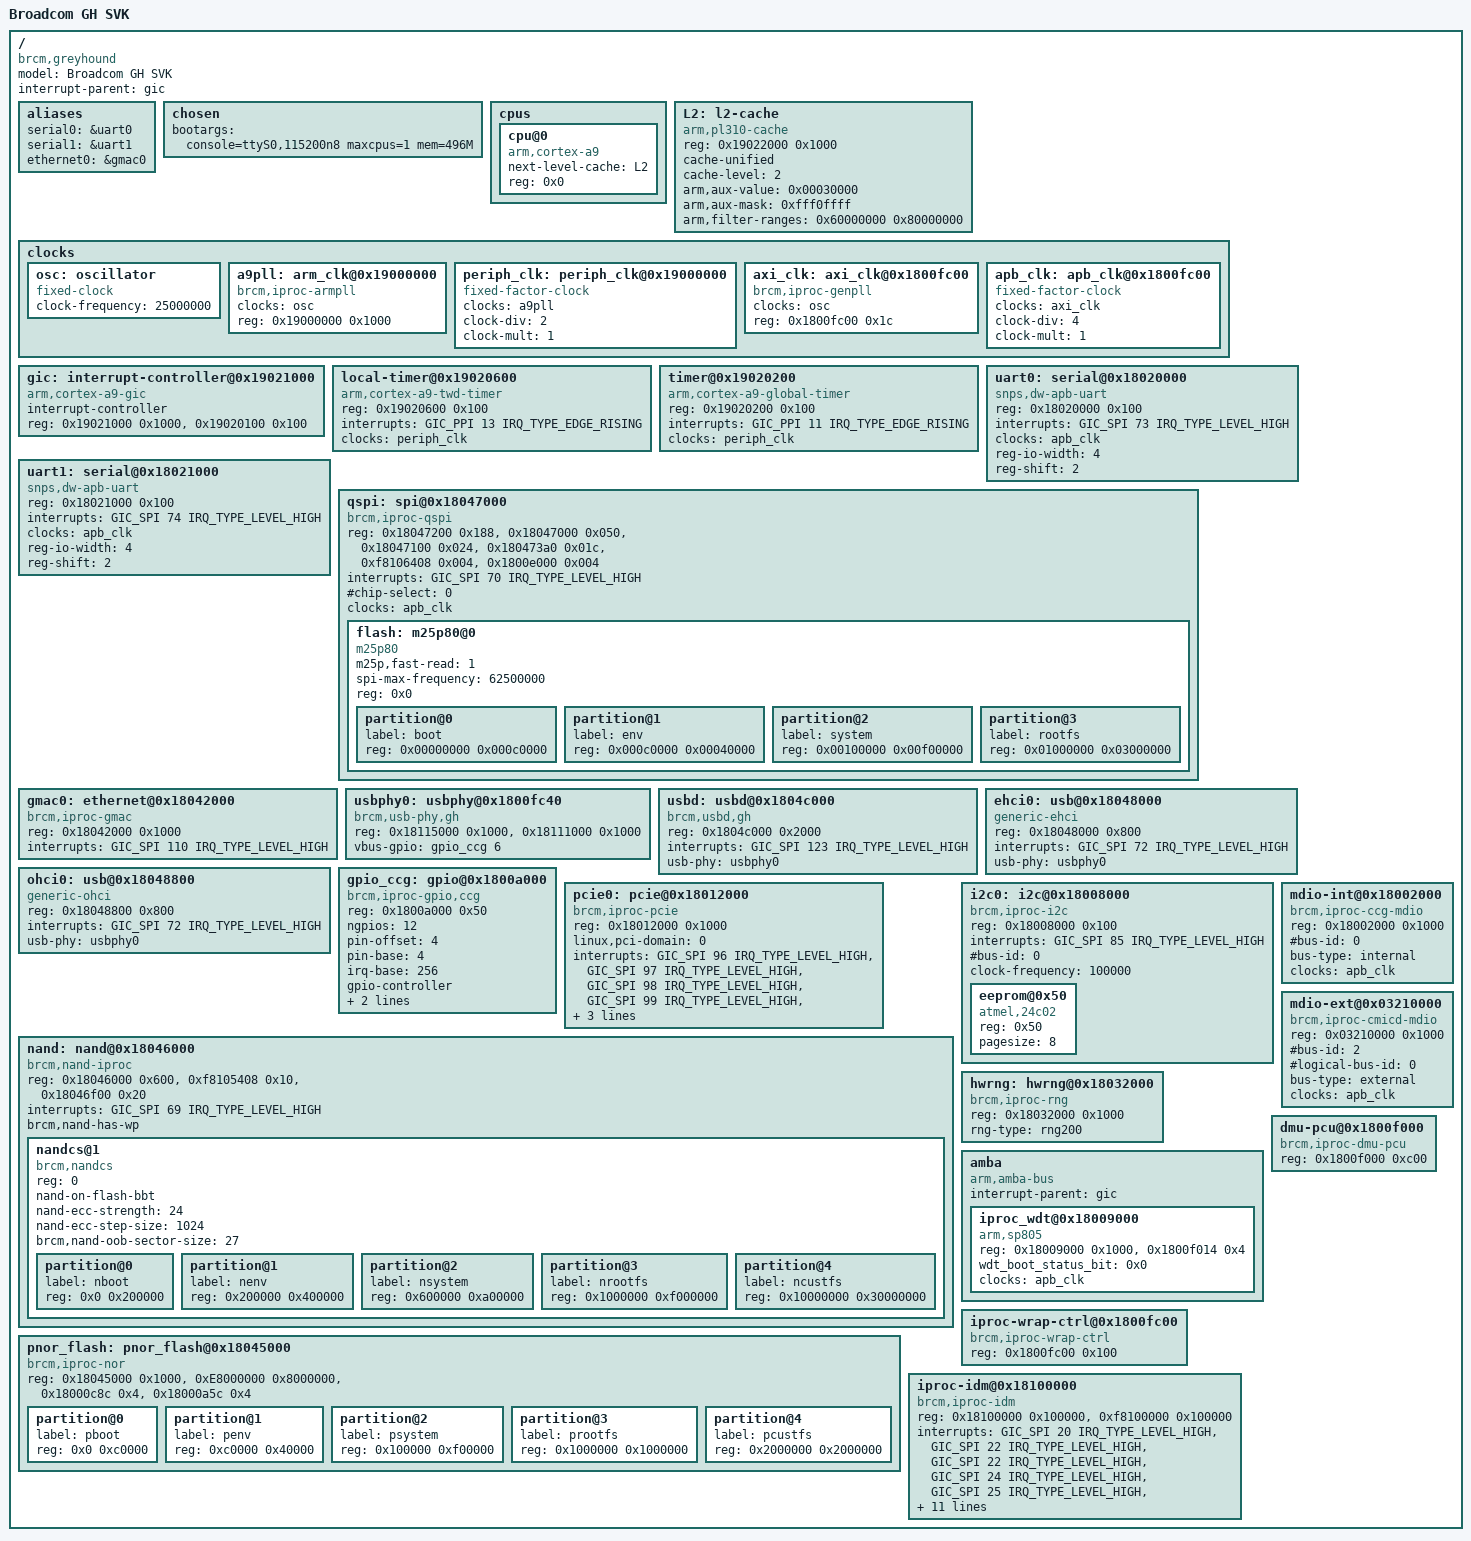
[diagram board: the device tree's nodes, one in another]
/*
 GH DTS
*/

/dts-v1/;

#include <dt-bindings/interrupt-controller/arm-gic.h>
#include <dt-bindings/gpio/gpio.h>
#include "skeleton.dtsi"


/ {
	model = "Broadcom GH SVK";
	compatible = "brcm,greyhound", "brcm,iproc-p7";
	interrupt-parent = <&gic>;

	aliases {
		serial0 = &uart0;
		serial1 = &uart1;
		ethernet0 = &gmac0;
	};
	
	chosen {
		bootargs = "console=ttyS0,115200n8 maxcpus=1 mem=496M";
	};

	cpus {
		#address-cells = <1>;
		#size-cells = <0>;

		cpu@0 {
			device_type = "cpu";
			compatible = "arm,cortex-a9";
			next-level-cache = <&L2>;
			reg = <0x0>;
		};
	};
  	
  	L2: l2-cache {
		compatible = "arm,pl310-cache";
		reg = <0x19022000 0x1000>;
		cache-unified;
		cache-level = <2>;
		/* aux register value */
		arm,aux-value = <0x00030000>;
		arm,aux-mask = <0xfff0ffff>;
		arm,filter-ranges = <0x60000000 0x80000000>;
		/*arm,data-latency = <2 2 2>;*/
		/*arm,tag-latency = <1 1 1>;*/
	};
  	
  	clocks {
		#address-cells = <1>;
		#size-cells = <1>;
		ranges;

		osc: oscillator {
			#clock-cells = <0>;
			compatible = "fixed-clock";
			clock-frequency = <25000000>;
		};

		a9pll: arm_clk@0x19000000 {
			#clock-cells = <0>;
			compatible = "brcm,iproc-armpll";
			clocks = <&osc>;
			reg = <0x19000000 0x1000>;
		};

		periph_clk: periph_clk@0x19000000 {
			#clock-cells = <0>;
			compatible = "fixed-factor-clock";
			clocks = <&a9pll>;
			clock-div = <2>;
			clock-mult = <1>;
		};
		
		axi_clk: axi_clk@0x1800fc00 {
			#clock-cells = <0>;
			compatible = "brcm,iproc-genpll";
			clocks = <&osc>;
			reg = <0x1800fc00 0x1c>;
		};

		apb_clk: apb_clk@0x1800fc00 {
			#clock-cells = <0>;
			compatible = "fixed-factor-clock";
			clocks = <&axi_clk>;
			clock-div = <4>;
			clock-mult = <1>;
		};		
	};
  	
  	gic: interrupt-controller@0x19021000 {
		compatible = "arm,cortex-a9-gic";
		#interrupt-cells = <3>;
		interrupt-controller;
		reg = <0x19021000 0x1000>, <0x19020100 0x100>;
	};
  	  
  	local-timer@0x19020600 {
		compatible = "arm,cortex-a9-twd-timer";
		reg = <0x19020600 0x100>;
		/* bits[15:8] of PPI interrupt is cpu mask corresponding to
		*  each of the 8 possible cpus attached to the GIC
		*/
		interrupts = <GIC_PPI 13 IRQ_TYPE_EDGE_RISING>;
		clocks = <&periph_clk>;
	};
  	
  	timer@0x19020200 {
		compatible = "arm,cortex-a9-global-timer";
		reg = <0x19020200 0x100>;
		interrupts = <GIC_PPI 11 IRQ_TYPE_EDGE_RISING>; 
		clocks = <&periph_clk>;
	};
	
	uart0: serial@0x18020000 {
		compatible = "snps,dw-apb-uart";
		reg = <0x18020000 0x100>;
		interrupts = <GIC_SPI 73 IRQ_TYPE_LEVEL_HIGH>;
		/*clock-frequency = <50000000>;*/
		clocks = <&apb_clk>;
		reg-io-width = <4>;
		reg-shift = <2>;
	};

	uart1: serial@0x18021000 {
		compatible = "snps,dw-apb-uart";
		reg = <0x18021000 0x100>;
		interrupts = <GIC_SPI 74 IRQ_TYPE_LEVEL_HIGH>;
		/*clock-frequency = <50000000>;*/
		clocks = <&apb_clk>;
		reg-io-width = <4>;
		reg-shift = <2>;
	};
		
	qspi: spi@0x18047000 {
		#address-cells = <1>;
		#size-cells = <0>;
		compatible = "brcm,iproc-qspi";
		reg = mspi_hw:<0x18047200 0x188>,
		      bspi_hw:<0x18047000 0x050>,
		  bspi_hw_raf:<0x18047100 0x024>,
		    qspi_intr:<0x180473a0 0x01c>,
		     idm_qspi:<0xf8106408 0x004>,
		       cru_hw:<0x1800e000 0x004>;
		interrupts = <GIC_SPI 70 IRQ_TYPE_LEVEL_HIGH>;
		#chip-select = <0>; 
		clocks = <&apb_clk>;
		clock-names = "apb_clk";
		flash: m25p80@0 {
			#address-cells = <1>;
			#size-cells = <1>;
			compatible = "m25p80";
			m25p,fast-read = <1>;
			spi-max-frequency = <62500000>;
			reg = <0x0>;
			partition@0 {
				label = "boot";
				reg = <0x00000000 0x000c0000>;
				/*read-only;*/
			};
			partition@1 {
				label = "env";
				reg = <0x000c0000 0x00040000>;
			};
			partition@2 {
				label = "system";
				reg = <0x00100000 0x00f00000>;
			};
			partition@3 {
				label = "rootfs";
				reg = <0x01000000 0x03000000>;
			};
		};
	};

	gmac0: ethernet@0x18042000 {
		compatible = "brcm,iproc-gmac";
		reg = <0x18042000 0x1000>;
		interrupts = <GIC_SPI 110 IRQ_TYPE_LEVEL_HIGH>;
	};

	usbphy0: usbphy@0x1800fc40 {
		#phy-cells = <0>;
		compatible = "brcm,usb-phy,gh";
		reg = idm_usb2h: <0x18115000 0x1000>,
			  idm_usb2d: <0x18111000 0x1000>;
		vbus-gpio = <&gpio_ccg 6 GPIO_ACTIVE_HIGH>;
	};

	usbd: usbd@0x1804c000 {
		compatible = "brcm,usbd,gh";
		reg = <0x1804c000 0x2000>;
		interrupts = <GIC_SPI 123 IRQ_TYPE_LEVEL_HIGH>;
		usb-phy = <&usbphy0>;
	};

	ehci0: usb@0x18048000 {
		compatible = "generic-ehci";
		reg = <0x18048000 0x800>;
		interrupts = <GIC_SPI 72 IRQ_TYPE_LEVEL_HIGH>;			
		usb-phy = <&usbphy0>;
	};
		
	ohci0: usb@0x18048800 {
		compatible = "generic-ohci";
		reg = <0x18048800 0x800>;
		interrupts = <GIC_SPI 72 IRQ_TYPE_LEVEL_HIGH>;			
		usb-phy = <&usbphy0>;
	};

	gpio_ccg: gpio@0x1800a000 {
		compatible = "brcm,iproc-gpio,ccg";
		#address-cells = <1>;
		#size-cells = <1>;
		#gpio-cells = <2>;
		reg = gpio: <0x1800a000 0x50>;
		ngpios = <12>;
		pin-offset = <4>;
		pin-base = <4>;
		irq-base = <256>; /* sw irq base for irq handlers */
		gpio-controller;
		interrupt-controller;
		interrupts = <GIC_SPI 84 IRQ_TYPE_LEVEL_HIGH>;
	};
	
	pcie0: pcie@0x18012000 {
		compatible = "brcm,iproc-pcie", "iproc-p7";
		reg = <0x18012000 0x1000>;
		linux,pci-domain = <0>;
		interrupts = <GIC_SPI 96 IRQ_TYPE_LEVEL_HIGH>,
			     <GIC_SPI 97 IRQ_TYPE_LEVEL_HIGH>,
			     <GIC_SPI 98 IRQ_TYPE_LEVEL_HIGH>,
			     <GIC_SPI 99 IRQ_TYPE_LEVEL_HIGH>,
			     <GIC_SPI 100 IRQ_TYPE_LEVEL_HIGH>,
			     <GIC_SPI 101 IRQ_TYPE_LEVEL_HIGH>;
		status = "okay"; 
		#address-cells = <3>;
		#size-cells = <2>;
		device_type = "pci";
		/*non-prefetchable mem space, pcie addr 0x0 0x20000000,
		* cpu addr 0x20000000, size 0x0 0x20000000
		*/  		
		ranges = <0x82000000 0 0x20000000 0x20000000 0 0x20000000>;	
		phy-addr = <0>;
	};

	nand: nand@0x18046000 {
		compatible = "brcm,nand-iproc", "brcm,brcmnand-v6.1";
		reg = <0x18046000 0x600>, <0xf8105408 0x10>, <0x18046f00 0x20>;
		reg-names = "nand", "iproc-idm", "iproc-ext";
		interrupts = <GIC_SPI 69 IRQ_TYPE_LEVEL_HIGH>;
		#address-cells = <1>;
		#size-cells = <0>;
		brcm,nand-has-wp;
		
		nandcs@1 {
			compatible = "brcm,nandcs";
			reg = <0>;
			nand-on-flash-bbt;
			/*nand-bus-width = <8>;*/
			nand-ecc-strength = <24>;
			nand-ecc-step-size = <1024>;
			brcm,nand-oob-sector-size = <27>;

			#address-cells = <1>;
			#size-cells = <1>;
			
			partition@0 {
				label = "nboot";
				reg = <0x0 0x200000>;
				/*read-only;*/
			};
			partition@1 {
				label = "nenv";
				reg = <0x200000 0x400000>;
			};
			partition@2 {
				label = "nsystem";
				reg = <0x600000 0xa00000>;
			};
			partition@3 {
				label = "nrootfs";
				reg = <0x1000000 0xf000000>;
			};
			partition@4 {
				label = "ncustfs";
				reg = <0x10000000 0x30000000>;
			};		
		};
	};

	pnor_flash: pnor_flash@0x18045000 {
		#address-cells = <1>;
		#size-cells = <1>;
		compatible = "brcm,iproc-nor";
		reg =	nor_regs: <0x18045000 0x1000>,
			nor_mem: <0xE8000000 0x8000000>,
			nor_sel: <0x18000c8c 0x4>,
			nor_strap: <0x18000a5c 0x4>;
		partition@0 {
			label = "pboot";
			reg = <0x0 0xc0000>;
			/*read-only;*/
		};
		partition@1 {
			label = "penv";
			reg = <0xc0000 0x40000>;
		};
		partition@2 {
			label = "psystem";
			reg = <0x100000 0xf00000>;
		};
		partition@3 {
			label = "prootfs";
			reg = <0x1000000 0x1000000>;
		};
		/* the second flash */
		partition@4 {
			label = "pcustfs";
			reg = <0x2000000 0x2000000>;
		};		
	};
	
	i2c0: i2c@0x18008000 {
		compatible = "brcm,iproc-i2c";
		reg = <0x18008000 0x100>;
		interrupts = <GIC_SPI 85 IRQ_TYPE_LEVEL_HIGH>;
		#bus-id = <0>;
		clock-frequency = <100000>;
		
		#address-cells = <1>;
		#size-cells = <0>;	
		eeprom@0x50 {
			compatible = "atmel,24c02";
			reg = <0x50>;
			pagesize = <8>;
		};
	};

	mdio-int@0x18002000 {
		compatible = "brcm,iproc-ccg-mdio";
		#address-cells = <1>;
		#size-cells = <1>;
		reg = <0x18002000 0x1000>;
		#bus-id = <0>;
		bus-type = "internal";
		clocks = <&apb_clk>;
		clock-names = "apb_clk";
	};
	
	/* cmicd cmic_common mdio */
	mdio-ext@0x03210000 {
		compatible = "brcm,iproc-cmicd-mdio";
		#address-cells = <1>;
		#size-cells = <1>;
		reg = <0x03210000 0x1000>;
		/* cmicd mdio needs #logical-bus-id and #bus-id (physical) */
		#bus-id = <2>;
		#logical-bus-id = <0>;
		bus-type = "external";
		clocks = <&apb_clk>;
		clock-names = "apb_clk";
	};
			
	hwrng: hwrng@0x18032000 {
		compatible = "brcm,iproc-rng";
		#address-cells = <1>;
		#size-cells = <1>;
		reg = <0x18032000 0x1000>;
		rng-type = "rng200";
	};
	
	amba {
		#address-cells = <1>;
		#size-cells = <1>;
		compatible = "arm,amba-bus", "simple-bus";
		interrupt-parent = <&gic>;
		ranges;

		iproc_wdt@0x18009000 {
			compatible = "arm,sp805", "arm,primecell";
			reg = iproc_wdt_base: <0x18009000 0x1000>,
	      		iproc_reset_reg: <0x1800f014 0x4>;
	      	wdt_boot_status_bit = <0x0>;	
			clocks = <&apb_clk>;
			/* should be "apb_pclk" according to 
			*Documentation/devicetree/bindings/arm/primecell.txt
			*/
			clock-names = "apb_pclk";
		};
	};
	
	dmu-pcu@0x1800f000 {
		compatible = "brcm,iproc-dmu-pcu";
		#address-cells = <1>;
		#size-cells = <1>;
		reg = <0x1800f000 0xc00>;
	};
	
	iproc-wrap-ctrl@0x1800fc00 {
		compatible = "brcm,iproc-wrap-ctrl";
		#address-cells = <1>;
		#size-cells = <1>;
		reg = <0x1800fc00 0x100>;
	};
	
	iproc-idm@0x18100000 {
		compatible = "brcm,iproc-idm";
		#address-cells = <1>;
		#size-cells = <1>;
		reg = idm0: <0x18100000 0x100000>,
			  idm1: <0xf8100000 0x100000>;
		interrupts = <GIC_SPI 20 IRQ_TYPE_LEVEL_HIGH>,
				<GIC_SPI 22 IRQ_TYPE_LEVEL_HIGH>,
				<GIC_SPI 22 IRQ_TYPE_LEVEL_HIGH>,
				<GIC_SPI 24 IRQ_TYPE_LEVEL_HIGH>,
				<GIC_SPI 25 IRQ_TYPE_LEVEL_HIGH>,
				<GIC_SPI 26 IRQ_TYPE_LEVEL_HIGH>,
				<GIC_SPI 27 IRQ_TYPE_LEVEL_HIGH>,
				<GIC_SPI 28 IRQ_TYPE_LEVEL_HIGH>,
				<GIC_SPI 30 IRQ_TYPE_LEVEL_HIGH>,
				<GIC_SPI 32 IRQ_TYPE_LEVEL_HIGH>,
				<GIC_SPI 36 IRQ_TYPE_LEVEL_HIGH>,
				<GIC_SPI 39 IRQ_TYPE_LEVEL_HIGH>,
				<GIC_SPI 46 IRQ_TYPE_LEVEL_HIGH>,
				<GIC_SPI 47 IRQ_TYPE_LEVEL_HIGH>,
				<GIC_SPI 48 IRQ_TYPE_LEVEL_HIGH>,
				<GIC_SPI 49 IRQ_TYPE_LEVEL_HIGH>;        			  
	};		
};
